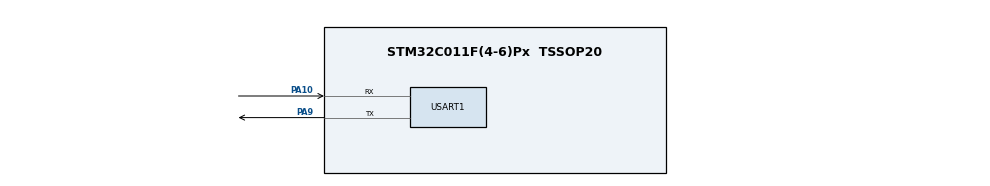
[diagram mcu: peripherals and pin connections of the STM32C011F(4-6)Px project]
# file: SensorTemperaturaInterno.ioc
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ADC1.Channel-0\#ChannelRegularConversion=ADC_CHANNEL_VREFINT
ADC1.Channel-1\#ChannelRegularConversion=ADC_CHANNEL_TEMPSENSOR
ADC1.ContinuousConvMode=DISABLE
ADC1.ExternalTrigConv=ADC_EXTERNALTRIG_T1_TRGO2
ADC1.NbrOfConversion=2
ADC1.NbrOfConversionFlag=1
ADC1.Rank-0\#ChannelRegularConversion=1
ADC1.Rank-1\#ChannelRegularConversion=2
ADC1.SamplingTime-0\#ChannelRegularConversion=ADC_SAMPLINGTIME_COMMON_1
ADC1.SamplingTime-1\#ChannelRegularConversion=ADC_SAMPLINGTIME_COMMON_1
ADC1.SamplingTimeCommon1=ADC_SAMPLETIME_160CYCLES_5
ADC1.SamplingTimeCommon2=ADC_SAMPLETIME_160CYCLES_5
ADC1.SelectedChannel=ADC_CHANNEL_TEMPSENSOR|ADC_CHANNEL_VREFINT
ADC1.master=1
Dma.ADC1.0.Direction=DMA_PERIPH_TO_MEMORY
Dma.ADC1.0.EventEnable=DISABLE
Dma.ADC1.0.Instance=DMA1_Channel1
Dma.ADC1.0.MemDataAlignment=DMA_MDATAALIGN_HALFWORD
Dma.ADC1.0.MemInc=DMA_MINC_ENABLE
Dma.ADC1.0.Mode=DMA_CIRCULAR
Dma.ADC1.0.PeriphDataAlignment=DMA_PDATAALIGN_HALFWORD
Dma.ADC1.0.PeriphInc=DMA_PINC_DISABLE
Dma.ADC1.0.Polarity=HAL_DMAMUX_REQ_GEN_RISING
Dma.ADC1.0.Priority=DMA_PRIORITY_LOW
Dma.ADC1.0.RequestNumber=1
Dma.ADC1.0.SignalID=NONE
Dma.ADC1.0.SyncEnable=DISABLE
Dma.ADC1.0.SyncPolarity=HAL_DMAMUX_SYNC_NO_EVENT
Dma.ADC1.0.SyncRequestNumber=1
Dma.ADC1.0.SyncSignalID=NONE
Dma.Request0=ADC1
Mcu.Family=STM32C0
Mcu.Name=STM32C011F(4-6)Px
Mcu.Package=TSSOP20
NVIC.ADC1_IRQn=true\:0\:0\:false\:false\:true\:true\:true\:true
NVIC.DMA1_Channel1_IRQn=true\:0\:0\:false\:false\:true\:false\:true\:true
PA10\ [PA12].Mode=Asynchronous
PA10\ [PA12].Signal=USART1_RX
PA13.Mode=Serial_Wire
PA13.Signal=DEBUG_SWDIO
PA14-BOOT0.Mode=Serial_Wire
PA14-BOOT0.Signal=DEBUG_SWCLK
PA9\ [PA11].Mode=Asynchronous
PA9\ [PA11].Signal=USART1_TX
ProjectManager.HeapSize=0x200
ProjectManager.StackSize=0x400
ProjectManager.TargetToolchain=STM32CubeIDE
RCC.ADCFreq_Value=48000000
RCC.AHBFreq_Value=48000000
RCC.CortexFreq_Value=48000000
RCC.EXTERNAL_CLOCK_VALUE=12288000
RCC.HCLKFreq_Value=48000000
RCC.HSE_VALUE=8000000
RCC.HSISYSCLKDivider=RCC_HSI_DIV1
RCC.HSI_VALUE=48000000
RCC.LSE_VALUE=32768
RCC.SYSCLKFreq_VALUE=48000000
TIM1.Period=960-1
TIM1.Prescaler=1000-1
TIM1.TIM_MasterOutputTrigger=TIM_TRGO_UPDATE
TIM1.TIM_MasterOutputTrigger2=TIM_TRGO2_UPDATE
USART1.VirtualMode-Asynchronous=VM_ASYNC
VP_ADC1_TempSens_Input.Mode=IN-TempSens
VP_ADC1_Vref_Input.Mode=IN-Vrefint
VP_SYS_VS_PINREMAP.Mode=PINREMAP
VP_SYS_VS_PINREMAP_10_12.Mode=PINREMAP_10_12
VP_TIM1_VS_ClockSourceINT.Mode=Internal
board=custom

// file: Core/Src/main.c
/* USER CODE BEGIN Header */
/**
  ******************************************************************************
  * @file           : main.c
  * @brief          : Main program body
  ******************************************************************************
  * @attention
  *
  * Copyright (c) 2024 STMicroelectronics.
  * All rights reserved.
  *
  * This software is licensed under terms that can be found in the LICENSE file
  * in the root directory of this software component.
  * If no LICENSE file comes with this software, it is provided AS-IS.
  *
  ******************************************************************************
  */
/* USER CODE END Header */
#include "main.h"

/* USER CODE BEGIN Includes */
#include "stdio.h"
#include "string.h"
/* USER CODE END Includes */

/* USER CODE BEGIN PD */
#define AVG_SLOPE (0.00253F) // 2.53 mV/°C
#define V_AT_30C  (0.76F)   // 0.76V at 30°C
#define V_REF_INT (1.12F)    // reference voltage
/* USER CODE END PD */

ADC_HandleTypeDef hadc1;
DMA_HandleTypeDef hdma_adc1;

TIM_HandleTypeDef htim1;

UART_HandleTypeDef huart1;

/* USER CODE BEGIN PV */
uint8_t UpdateEvent = 0;
uint16_t AD_RES[2];
float Temperature, V_Sense, V_Ref;
char TxBuffer[30];
/* USER CODE END PV */

void SystemClock_Config(void);
static void MX_GPIO_Init(void);
static void MX_DMA_Init(void);
static void MX_ADC1_Init(void);
static void MX_TIM1_Init(void);
static void MX_USART1_UART_Init(void);

int main(void)
{

  /* MCU Configuration--------------------------------------------------------*/

  /* Reset of all peripherals, Initializes the Flash interface and the Systick. */
  HAL_Init();

  /* Configure the system clock */
  SystemClock_Config();

  /* Initialize all configured peripherals */
  MX_GPIO_Init();
  MX_DMA_Init();
  MX_ADC1_Init();
  MX_TIM1_Init();
  MX_USART1_UART_Init();
  /* USER CODE BEGIN 2 */
  HAL_TIM_Base_Start(&htim1); // Start Timer1 (Trigger Source For ADC1)
  HAL_ADCEx_Calibration_Start(&hadc1);
  /* USER CODE END 2 */

  /* Infinite loop */
  while (1)
  {

    /* USER CODE BEGIN 3 */
	  HAL_ADC_Start_DMA(&hadc1, (uint32_t*)AD_RES, 2);   // Start ADC Conversion
	  if(UpdateEvent){
		// Calculate The Temperature
		V_Ref = (float)((V_REF_INT * 4095.0) / AD_RES[0]);
		V_Sense = (float)(AD_RES[1] * V_Ref) / 4095.0;
		Temperature = (((V_AT_30C  - V_Sense) * 1000.0) / AVG_SLOPE) + 30.0;
		int parte_inteira = (int)Temperature/1000.0;
		int parte_decimal = (int)((Temperature - parte_inteira) * 100.0); // Uma casa decimal

	   // Send The Result To PC Over Serial Port
	   sprintf(TxBuffer, "Temperatura: %d.%02d\r\n", parte_inteira, parte_decimal);
	   HAL_UART_Transmit(&huart1, (uint8_t*)TxBuffer, strlen(TxBuffer), 100);
	   UpdateEvent = 0;
   }
  }
  /* USER CODE END 3 */
}

void HAL_ADC_ConvCpltCallback(ADC_HandleTypeDef* hadc)
{
    UpdateEvent = 1;
}

void SystemClock_Config(void)
{
  RCC_OscInitTypeDef RCC_OscInitStruct = {0};
  RCC_ClkInitTypeDef RCC_ClkInitStruct = {0};

  /** Initializes the RCC Oscillators according to the specified parameters
  * in the RCC_OscInitTypeDef structure.
  */
  RCC_OscInitStruct.OscillatorType = RCC_OSCILLATORTYPE_HSI;
  RCC_OscInitStruct.HSIState = RCC_HSI_ON;
  RCC_OscInitStruct.HSIDiv = RCC_HSI_DIV1;
  RCC_OscInitStruct.HSICalibrationValue = RCC_HSICALIBRATION_DEFAULT;
  if (HAL_RCC_OscConfig(&RCC_OscInitStruct) != HAL_OK)
  {
    Error_Handler();
  }

  /** Initializes the CPU, AHB and APB buses clocks
  */
  RCC_ClkInitStruct.ClockType = RCC_CLOCKTYPE_HCLK|RCC_CLOCKTYPE_SYSCLK
                              |RCC_CLOCKTYPE_PCLK1;
  RCC_ClkInitStruct.SYSCLKSource = RCC_SYSCLKSOURCE_HSI;
  RCC_ClkInitStruct.SYSCLKDivider = RCC_SYSCLK_DIV1;
  RCC_ClkInitStruct.AHBCLKDivider = RCC_HCLK_DIV1;
  RCC_ClkInitStruct.APB1CLKDivider = RCC_APB1_DIV1;

  if (HAL_RCC_ClockConfig(&RCC_ClkInitStruct, FLASH_LATENCY_1) != HAL_OK)
  {
    Error_Handler();
  }
}

static void MX_ADC1_Init(void)
{

  ADC_ChannelConfTypeDef sConfig = {0};

  /** Configure the global features of the ADC (Clock, Resolution, Data Alignment and number of conversion)
  */
  hadc1.Instance = ADC1;
  hadc1.Init.ClockPrescaler = ADC_CLOCK_SYNC_PCLK_DIV2;
  hadc1.Init.Resolution = ADC_RESOLUTION_12B;
  hadc1.Init.DataAlign = ADC_DATAALIGN_RIGHT;
  hadc1.Init.ScanConvMode = ADC_SCAN_ENABLE;
  hadc1.Init.EOCSelection = ADC_EOC_SINGLE_CONV;
  hadc1.Init.LowPowerAutoWait = DISABLE;
  hadc1.Init.LowPowerAutoPowerOff = DISABLE;
  hadc1.Init.ContinuousConvMode = DISABLE;
  hadc1.Init.NbrOfConversion = 2;
  hadc1.Init.DiscontinuousConvMode = DISABLE;
  hadc1.Init.ExternalTrigConv = ADC_EXTERNALTRIG_T1_TRGO2;
  hadc1.Init.ExternalTrigConvEdge = ADC_EXTERNALTRIGCONVEDGE_RISING;
  hadc1.Init.DMAContinuousRequests = DISABLE;
  hadc1.Init.Overrun = ADC_OVR_DATA_PRESERVED;
  hadc1.Init.SamplingTimeCommon1 = ADC_SAMPLETIME_160CYCLES_5;
  hadc1.Init.SamplingTimeCommon2 = ADC_SAMPLETIME_160CYCLES_5;
  hadc1.Init.OversamplingMode = DISABLE;
  hadc1.Init.TriggerFrequencyMode = ADC_TRIGGER_FREQ_HIGH;
  if (HAL_ADC_Init(&hadc1) != HAL_OK)
  {
    Error_Handler();
  }

  /** Configure Regular Channel
  */
  sConfig.Channel = ADC_CHANNEL_VREFINT;
  sConfig.Rank = ADC_REGULAR_RANK_1;
  sConfig.SamplingTime = ADC_SAMPLINGTIME_COMMON_1;
  if (HAL_ADC_ConfigChannel(&hadc1, &sConfig) != HAL_OK)
  {
    Error_Handler();
  }

  /** Configure Regular Channel
  */
  sConfig.Channel = ADC_CHANNEL_TEMPSENSOR;
  sConfig.Rank = ADC_REGULAR_RANK_2;
  if (HAL_ADC_ConfigChannel(&hadc1, &sConfig) != HAL_OK)
  {
    Error_Handler();
  }

}

static void MX_TIM1_Init(void)
{

  TIM_ClockConfigTypeDef sClockSourceConfig = {0};
  TIM_MasterConfigTypeDef sMasterConfig = {0};

  htim1.Instance = TIM1;
  htim1.Init.Prescaler = 1000-1;
  htim1.Init.CounterMode = TIM_COUNTERMODE_UP;
  htim1.Init.Period = 960-1;
  htim1.Init.ClockDivision = TIM_CLOCKDIVISION_DIV1;
  htim1.Init.RepetitionCounter = 0;
  htim1.Init.AutoReloadPreload = TIM_AUTORELOAD_PRELOAD_DISABLE;
  if (HAL_TIM_Base_Init(&htim1) != HAL_OK)
  {
    Error_Handler();
  }
  sClockSourceConfig.ClockSource = TIM_CLOCKSOURCE_INTERNAL;
  if (HAL_TIM_ConfigClockSource(&htim1, &sClockSourceConfig) != HAL_OK)
  {
    Error_Handler();
  }
  sMasterConfig.MasterOutputTrigger = TIM_TRGO_UPDATE;
  sMasterConfig.MasterOutputTrigger2 = TIM_TRGO2_UPDATE;
  sMasterConfig.MasterSlaveMode = TIM_MASTERSLAVEMODE_DISABLE;
  if (HAL_TIMEx_MasterConfigSynchronization(&htim1, &sMasterConfig) != HAL_OK)
  {
    Error_Handler();
  }

}

static void MX_USART1_UART_Init(void)
{

  huart1.Instance = USART1;
  huart1.Init.BaudRate = 115200;
  huart1.Init.WordLength = UART_WORDLENGTH_8B;
  huart1.Init.StopBits = UART_STOPBITS_1;
  huart1.Init.Parity = UART_PARITY_NONE;
  huart1.Init.Mode = UART_MODE_TX_RX;
  huart1.Init.HwFlowCtl = UART_HWCONTROL_NONE;
  huart1.Init.OverSampling = UART_OVERSAMPLING_16;
  huart1.Init.OneBitSampling = UART_ONE_BIT_SAMPLE_DISABLE;
  huart1.Init.ClockPrescaler = UART_PRESCALER_DIV1;
  huart1.AdvancedInit.AdvFeatureInit = UART_ADVFEATURE_NO_INIT;
  if (HAL_UART_Init(&huart1) != HAL_OK)
  {
    Error_Handler();
  }
  if (HAL_UARTEx_SetTxFifoThreshold(&huart1, UART_TXFIFO_THRESHOLD_1_8) != HAL_OK)
  {
    Error_Handler();
  }
  if (HAL_UARTEx_SetRxFifoThreshold(&huart1, UART_RXFIFO_THRESHOLD_1_8) != HAL_OK)
  {
    Error_Handler();
  }
  if (HAL_UARTEx_DisableFifoMode(&huart1) != HAL_OK)
  {
    Error_Handler();
  }

}

static void MX_DMA_Init(void)
{

  /* DMA controller clock enable */
  __HAL_RCC_DMA1_CLK_ENABLE();

  /* DMA interrupt init */
  /* DMA1_Channel1_IRQn interrupt configuration */
  HAL_NVIC_SetPriority(DMA1_Channel1_IRQn, 0, 0);
  HAL_NVIC_EnableIRQ(DMA1_Channel1_IRQn);

}

static void MX_GPIO_Init(void)
{

  /* GPIO Ports Clock Enable */
  __HAL_RCC_GPIOA_CLK_ENABLE();

}

void Error_Handler(void)
{
  __disable_irq();
  while (1)
  {
  }
}
